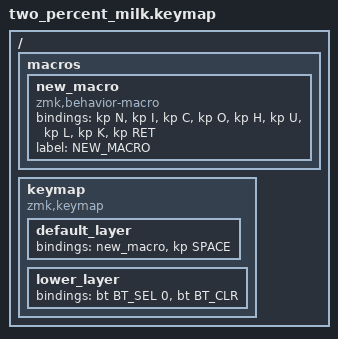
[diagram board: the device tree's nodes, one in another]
/*
 * Copyright (c) 2022 The ZMK Contributors
 *
 * SPDX-License-Identifier: MIT
 */

#include <behaviors.dtsi>
#include <dt-bindings/zmk/bt.h>
#include <dt-bindings/zmk/keys.h>

/ {
    macros {
        new_macro: new_macro {
            compatible = "zmk,behavior-macro";
            #binding-cells = <0>;
            bindings = <&kp N &kp I &kp C &kp O &kp H &kp U &kp L &kp K &kp RET>;
            label = "NEW_MACRO";
        };
    };

    keymap {
        compatible = "zmk,keymap";

        default_layer {
            bindings = <
&new_macro  &kp SPACE
            >;
        };

        lower_layer {
            bindings = <
&bt BT_SEL 0  &bt BT_CLR
            >;
        };
    };
};
